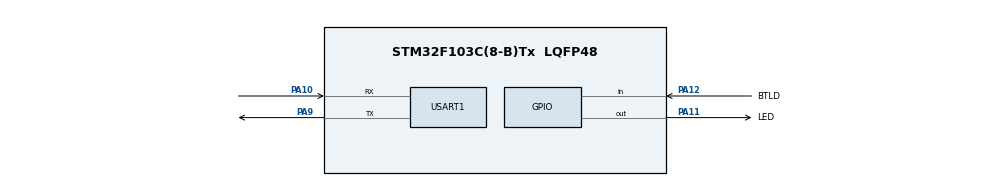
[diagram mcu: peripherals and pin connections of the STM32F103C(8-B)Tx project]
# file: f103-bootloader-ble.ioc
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Mcu.Family=STM32F1
Mcu.Name=STM32F103C(8-B)Tx
Mcu.Package=LQFP48
NVIC.PriorityGroup=NVIC_PRIORITYGROUP_4
PA10.Mode=Asynchronous
PA10.Signal=USART1_RX
PA11.GPIO_Label=LED
PA11.GPIO_ModeDefaultOutputPP=GPIO_MODE_OUTPUT_OD
PA11.GPIO_PuPd=GPIO_NOPULL
PA11.Signal=GPIO_Output
PA12.GPIO_Label=BTLD
PA12.Signal=GPIO_Input
PA13.Mode=Serial_Wire
PA13.Signal=SYS_JTMS-SWDIO
PA14.Mode=Serial_Wire
PA14.Signal=SYS_JTCK-SWCLK
PA9.Mode=Asynchronous
PA9.Signal=USART1_TX
PD0-OSC_IN.Mode=HSE-External-Oscillator
PD0-OSC_IN.Signal=RCC_OSC_IN
PD1-OSC_OUT.Mode=HSE-External-Oscillator
PD1-OSC_OUT.Signal=RCC_OSC_OUT
ProjectManager.HeapSize=0x200
ProjectManager.StackSize=0x400
ProjectManager.TargetToolchain=STM32CubeIDE
RCC.APB1Freq_Value=8000000
RCC.APB2Freq_Value=8000000
USART1.VirtualMode=VM_ASYNC
board=custom

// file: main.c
/* USER CODE BEGIN Header */
/**
  ******************************************************************************
  * @file           : main.c
  * @brief          : Main program body
  ******************************************************************************
  * @attention
  *
  * Copyright (c) 2023 STMicroelectronics.
  * All rights reserved.
  *
  * This software is licensed under terms that can be found in the LICENSE file
  * in the root directory of this software component.
  * If no LICENSE file comes with this software, it is provided AS-IS.
  *
  ******************************************************************************
  */
//#define gotway
#define board01
/* USER CODE END Header */
#include "main.h"

/* USER CODE BEGIN Includes */
//#include "xmodem.h"
//#include "uart.h"
#include "gupdater.h"
//#include "flash.h"
/* USER CODE END Includes */

UART_HandleTypeDef huart1;

void SystemClock_Config(void);
static void MX_GPIO_Init(void);
static void MX_USART1_UART_Init(void);

/* USER CODE BEGIN 0 */
void uart_transmit_str(uint8_t *data) {
  uint16_t length = 0u;

  while ('\0' != data[length]) length++;
  //HAL_UART_Transmit(&huart1, data, length, UART_TIMEOUT);
  HAL_UART_Transmit(&huart1, data, length, 100);
}
/* USER CODE END 0 */

int main(void)
{

  /* MCU Configuration--------------------------------------------------------*/

  /* Reset of all peripherals, Initializes the Flash interface and the Systick. */
  HAL_Init();

  /* Configure the system clock */
  SystemClock_Config();

  /* Initialize all configured peripherals */
  MX_GPIO_Init();
  MX_USART1_UART_Init();
  /* USER CODE BEGIN 2 */
  HAL_GPIO_WritePin(LED_GPIO_Port, LED_Pin, GPIO_PIN_SET);
  uart_transmit_str((uint8_t*)"# -=* UART Bootloader 0.2*=-\r\n");

  /* If the button is pressed, then jump to the user application,
   * otherwise stay in the bootloader. */
  if(HAL_GPIO_ReadPin(BTLD_GPIO_Port, BTLD_Pin)) {
    uart_transmit_str((uint8_t*)"# Goto app...\r\n");
    //HAL_Delay(1000);
    flash_jump_to_app();
  }

  HAL_GPIO_WritePin(PWRON_Port, PWRON_Pin, GPIO_PIN_SET);

  /* USER CODE END 2 */

  /* Infinite loop */
  /* USER CODE BEGIN WHILE */
  while (1)
  {
	    /* Turn on the green LED to indicate, that we are in bootloader mode.*/
	    //HAL_GPIO_WritePin(GPIOC, LED_Pin, GPIO_PIN_RESET);
	    /* Ask for new data and start the Xmodem protocol. */
	    uart_transmit_str((uint8_t*)"# Send a binary file to update the firmware.\r\n");
	    //xmodem_receive();
	    if (updater_receiver() == CH_END) {
            uart_transmit_str((uint8_t*)"# Firmware updated!\r\n");
            uart_transmit_str((uint8_t*)"# Goto app...\r\n");
            flash_jump_to_app();
	    }
	    /* We only exit the xmodem protocol, if there are any errors.
	     * In that case, notify the user and start over. */
	    uart_transmit_str((uint8_t*)"#\n\rFailed... Please try again.\n\r");
    /* USER CODE END WHILE */

  }
}

void SystemClock_Config(void)
{
  RCC_OscInitTypeDef RCC_OscInitStruct = {0};
  RCC_ClkInitTypeDef RCC_ClkInitStruct = {0};

  /** Initializes the RCC Oscillators according to the specified parameters
  * in the RCC_OscInitTypeDef structure.
  */
  RCC_OscInitStruct.OscillatorType = RCC_OSCILLATORTYPE_HSI;
  RCC_OscInitStruct.HSIState = RCC_HSI_ON;
  RCC_OscInitStruct.HSICalibrationValue = RCC_HSICALIBRATION_DEFAULT;
  RCC_OscInitStruct.PLL.PLLState = RCC_PLL_NONE;
  if (HAL_RCC_OscConfig(&RCC_OscInitStruct) != HAL_OK)
  {
    Error_Handler();
  }
  /** Initializes the CPU, AHB and APB buses clocks
  */
  RCC_ClkInitStruct.ClockType = RCC_CLOCKTYPE_HCLK|RCC_CLOCKTYPE_SYSCLK
                              |RCC_CLOCKTYPE_PCLK1|RCC_CLOCKTYPE_PCLK2;
  RCC_ClkInitStruct.SYSCLKSource = RCC_SYSCLKSOURCE_HSI;
  RCC_ClkInitStruct.AHBCLKDivider = RCC_SYSCLK_DIV1;
  RCC_ClkInitStruct.APB1CLKDivider = RCC_HCLK_DIV1;
  RCC_ClkInitStruct.APB2CLKDivider = RCC_HCLK_DIV1;

  if (HAL_RCC_ClockConfig(&RCC_ClkInitStruct, FLASH_LATENCY_0) != HAL_OK)
  {
    Error_Handler();
  }
}

static void MX_USART1_UART_Init(void)
{

  huart1.Instance = USART1;
  huart1.Init.BaudRate = 115200;
  huart1.Init.WordLength = UART_WORDLENGTH_8B;
  huart1.Init.StopBits = UART_STOPBITS_1;
  huart1.Init.Parity = UART_PARITY_NONE;
  huart1.Init.Mode = UART_MODE_TX_RX;
  huart1.Init.HwFlowCtl = UART_HWCONTROL_NONE;
  huart1.Init.OverSampling = UART_OVERSAMPLING_16;
  if (HAL_UART_Init(&huart1) != HAL_OK)
  {
    Error_Handler();
  }

}

static void MX_GPIO_Init(void)
{
  GPIO_InitTypeDef GPIO_InitStruct = {0};

  /* GPIO Ports Clock Enable */
  __HAL_RCC_GPIOD_CLK_ENABLE();
  __HAL_RCC_GPIOA_CLK_ENABLE();
  __HAL_RCC_GPIOB_CLK_ENABLE();
  __HAL_RCC_GPIOC_CLK_ENABLE();

  /*Configure GPIO pin Output Level */
  HAL_GPIO_WritePin(LED_GPIO_Port, LED_Pin, GPIO_PIN_RESET);
  HAL_GPIO_WritePin(PWRON_Port, PWRON_Pin, GPIO_PIN_RESET);

  /*Configure GPIO pin : LED_Pin */
  GPIO_InitStruct.Pin = LED_Pin;
  GPIO_InitStruct.Mode = GPIO_MODE_OUTPUT_OD;
  GPIO_InitStruct.Pull = GPIO_NOPULL;
  GPIO_InitStruct.Speed = GPIO_SPEED_FREQ_LOW;
  HAL_GPIO_Init(LED_GPIO_Port, &GPIO_InitStruct);

  GPIO_InitStruct.Pin = PWRON_Pin;
  HAL_GPIO_Init(PWRON_Port, &GPIO_InitStruct);

  /*Configure GPIO pin : BTLD_Pin */
  GPIO_InitStruct.Pin = BTLD_Pin;
  GPIO_InitStruct.Mode = GPIO_MODE_INPUT;
  //GPIO_InitStruct.Pull = GPIO_NOPULL;
  GPIO_InitStruct.Pull = GPIO_PULLUP;
  HAL_GPIO_Init(BTLD_GPIO_Port, &GPIO_InitStruct);

}

void Error_Handler(void)
{
  __disable_irq();
  while (1)
  {
  }
}
